# STM32WB55xx register map
File version: 1.0
Registers are 32-bit, read-write, reset 0x0 unless marked. A register's access mark holds for its fields unless they carry their own. Offsets are from the block's base; [hi:lo] are bit positions; {n}, {i} and the like mark numbered series.

## RTC — Real-Time Clock
Base 0x40002800
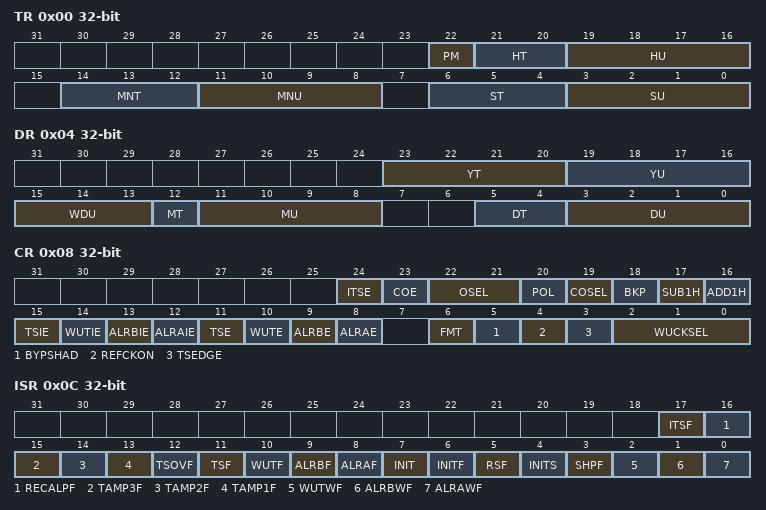
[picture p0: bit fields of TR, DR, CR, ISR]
0x00 TR — RTC time register
  [22] PM — AM/PM notation
    0=AM_OR_24 (AM or 24-hour format); 1=PM
  [21:20] HT — Hour tens in BCD format
  [19:16] HU — Hour units in BCD format
  [14:12] MNT — Minute tens in BCD format
  [11:8] MNU — Minute unit in BCD format
  [6:4] ST — Second tens in BCD format
  [3:0] SU — Second units in BCD format
0x04 DR — RTC date register
  [23:20] YT — Year tens in BCD format
  [19:16] YU — Years units in BCD format
  [15:13] WDU — Week day units
  [12] MT — Month tens in BCD format
  [11:8] MU — Month units in BCD format
  [5:4] DT — Date tens in BCD format
  [3:0] DU — Date units in BCD format
0x08 CR — RTC control register
  [24] ITSE — Timestamp on internal event enable
  [23] COE — Calibration output enable
  [22:21] OSEL — Output selection
    0=DISABLE (Output disabled); 1=ALMA (Alarm A output enabled); 2=ALMB (Alarm B output enabled); 3=WAKEUP (Wakeup output enabled)
  [20] POL — Output polarity
    0=HIGH (Pin is high when ALRAF/ALRBF/WUTF is asserted (depending on OSEL)); 1=LOW (Pin is low when ALRAF/ALRBF/WUTF is asserted (depending on OSEL))
  [19] COSEL — Calibration output selection
  [18] BKP — Backup
  [17] SUB1H — Subtract 1 hour (winter time change)
  [16] ADD1H — Add 1 hour (summer time change)
  [15] TSIE — Time-stamp interrupt enable
  [14] WUTIE — Wakeup timer interrupt enable
  [13] ALRBIE — Alarm B interrupt enable
  [12] ALRAIE — Alarm A interrupt enable
  [11] TSE — Timestamp on RTC TS input edge enable
  [10] WUTE — Wakeup timer enable
  [9] ALRBE — Alarm B enable
  [8] ALRAE — Alarm A enable
  [6] FMT — Hour AM/PM or 24H format
    0=HOURFORMAT_24HOUR (24 hour/day format); 1=AMPM (AM/PM hour format)
  [5] BYPSHAD — Bypass the shadow registers
  [4] REFCKON — RTC_REFIN reference clock detection enable (50 or 60 Hz)
  [3] TSEDGE — Timestamp event active edge
    0=RISING (RTC_TS input rising edge generates a time-stamp event); 1=FALLING (RTC_TS input falling edge generates a time-stamp event)
  [2:0] WUCKSEL — Wakekup clock selection
    0=DIV_16 (RTC/16 clock is selected); 1=DIV_8 (RTC/8 clock is selected); 2=DIV_4 (RTC/4 clock is selected); 3=DIV_2 (RTC/2 clock is selected); 4=CKSPRE (ck_spre (usually 1 Hz) clock is selected); 6=CKSPRE_WUT (ck_spre (usually 1 Hz) clock is selected and 2exp16 is added to the WUT counter value)
0x0C ISR — RTC initialization and status register
  [17] ITSF — Internal timestamp flag
  [16] RECALPF — Recalibration pending flag
  [15] TAMP3F — RTC_TAMP3 detection flag
  [14] TAMP2F — RTC_TAMP2 detection flag
  [13] TAMP1F — RTC_TAMP1 detection flag
  [12] TSOVF — Timestamp overflow flag
  [11] TSF — Timestamp flag
  [10] WUTF — Wakeup timer flag
  [9] ALRBF — Alarm B flag
  [8] ALRAF — Alarm A flag
  [7] INIT — Initialization mode
  [6] INITF — Initialization flag
  [5] RSF — Registers synchronization flag
  [4] INITS — Initialization status flag
  [3] SHPF — Shift operation pending
  [2] WUTWF — Wakeup timer write flag
  [1] ALRBWF — Alarm B write flag
  [0] ALRAWF — Alarm A write flag
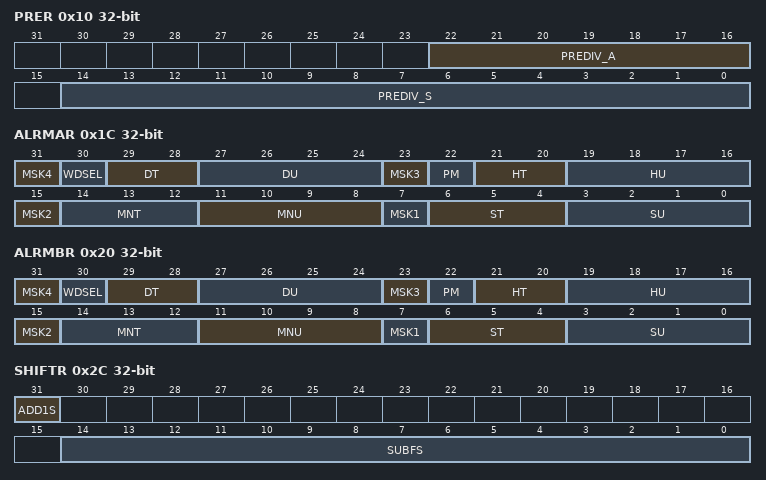
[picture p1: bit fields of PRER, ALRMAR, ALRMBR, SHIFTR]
0x10 PRER — RTC prescaler register
  [22:16] PREDIV_A — Asynchronous prescaler factor
  [14:0] PREDIV_S — Synchronous prescaler factor
0x14 WUTR — RTC wakeup timer register
  [15:0] WUT — Wakeup auto-reload value bits
0x1C ALRMAR — RTC alarm A register
  [31] MSK4 — Alarm A date mask
  [30] WDSEL — Alarm A week day selection
  [29:28] DT — Alarm A date tens in BCD format
  [27:24] DU — Alarm A date units in BCD format
  [23] MSK3 — Alarm A hours mask
  [22] PM — Alarm A AM/PM or 24H format
    0=AM (AM or 24-hour format); 1=PM
  [21:20] HT — Alarm A hour tens in BCD format
  [19:16] HU — Alarm A hour units in BCD format
  [15] MSK2 — Alarm A minutes mask
  [14:12] MNT — Alarm A minute tens in BCD format
  [11:8] MNU — Alarm A minute units in BCD format
  [7] MSK1 — Alarm A seconds mask
  [6:4] ST — Alarm A second tens in BCD format
  [3:0] SU — Alarm A second units in BCD format
0x20 ALRMBR — RTC alarm B register
  [31] MSK4 — Alarm B date mask
  [30] WDSEL — Alarm B week day selection
  [29:28] DT — Alarm B data tens in BCD format
  [27:24] DU — Alarm B data units or day in BCD format
  [23] MSK3 — Alarm B hour mask
  [22] PM — Alarm B AM/PM or 24H format
    0=AM (AM or 24-hour format); 1=PM
  [21:20] HT — Alarm B hour tens in BCD format
  [19:16] HU — Alarm B hour units in BCD format
  [15] MSK2 — Alarm B minutes mask
  [14:12] MNT — Alarm B minute tens in BCD format
  [11:8] MNU — Alarm B minute units in BCD format
  [7] MSK1 — Alarm B seconds mask
  [6:4] ST — Alarm B second tens in BCD format
  [3:0] SU — Alarm B second units in BCD format
0x24 WPR — RTC write protection register
  [7:0] KEY — Write protection key
0x28 SSR — RTC sub second register
  [15:0] SS — Sub second value
0x2C SHIFTR — RTC shift control register
  [31] ADD1S — Add on second
  [14:0] SUBFS — Subtract a fraction of a second
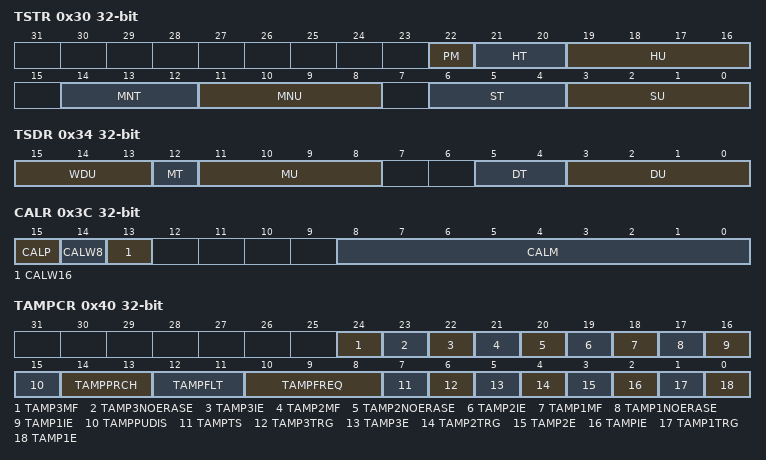
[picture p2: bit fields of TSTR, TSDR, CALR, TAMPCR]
0x30 TSTR — RTC time stamp time register
  [22] PM — Timestamp AM/PM or 24H format
    0=AM (AM or 24-hour format); 1=PM
  [21:20] HT — Timestamp hour tens in BCD format
  [19:16] HU — Timestamp hour units in BCD format
  [14:12] MNT — Timestamp minute tens in BCD format
  [11:8] MNU — Timestamp minute units in BCD format
  [6:4] ST — Timestamp second tens in BCD format
  [3:0] SU — Timestamp second units in BCD format
0x34 TSDR — RTC time stamp date register
  [15:13] WDU — Timestamp week day units
  [12] MT — Timestamp month tens in BCD format
  [11:8] MU — Timestamp month units in BCD format
  [5:4] DT — Timestamp date tens in BCD format
  [3:0] DU — Timestamp date units in BCD format
0x38 TSSSR — RTC time-stamp sub second register
  [15:0] SS — Timestamp sub second value
0x3C CALR — RTC calibration register
  [15] CALP — Increase frequency of RTC 488.5 ppm
    0=NONE (No RTCCLK pulses are added); 1=SET (One RTCCLK pulse is effectively inserted every 2exp11 pulses (frequency increased by 488.5 ppm))
  [14] CALW8 — Use a 8-second calibration cycle period
  [13] CALW16 — Use a 16-second calibration cycle period
  [8:0] CALM — Calibration minus
0x40 TAMPCR — RTC tamper configuration register
  [24] TAMP3MF — Tamper 3 generates a trigger event
  [23] TAMP3NOERASE — Tamper 3 no erase backup registers
  [22] TAMP3IE — Tamper 3 interrupt enable
  [21] TAMP2MF — Tamper 2 generates a trigger event
  [20] TAMP2NOERASE — Tamper 2 no erase backup registers
  [19] TAMP2IE — Tamper 2 interrupt enable
  [18] TAMP1MF — Tamper 1 generates a trigger event
  [17] TAMP1NOERASE — Tamper 1 no erase backup registers
  [16] TAMP1IE — Tamper 1 interrupt enable
  [15] TAMPPUDIS — RTC_TAMPx pull-up disable
  [14:13] TAMPPRCH — RTC_TAMPx precharge duration
    0=DURATION_1RTCCLK (Tamper pins are pre-charged before sampling during 1 RTCCLK cycle); 1=DURATION_2RTCCLK (Tamper pins are pre-charged before sampling during 2 RTCCLK cycles); 2=DURATION_4RTCCLK (Tamper pins are pre-charged before sampling during 4 RTCCLK cycles); 3=DURATION_8RTCCLK (Tamper pins are pre-charged before sampling during 8 RTCCLK cycles)
  [12:11] TAMPFLT — RTC_TAMPx filter count
    0=DISABLE (Tamper filter is disabled); 1=FILTER_2SAMPLE (Tamper is activated after 2 consecutive samples at the active level); 2=FILTER_4SAMPLE (Tamper is activated after 4 consecutive samples at the active level); 3=FILTER_8SAMPLE (Tamper is activated after 8 consecutive samples at the active level.)
  [10:8] TAMPFREQ — Tamper sampling frequency
    0=SAMPLFREQDIV_32768 (Each of the tamper inputs are sampled with a frequency = RTCCLK / 32768); 1=SAMPLFREQDIV_16384 (Each of the tamper inputs are sampled with a frequency = RTCCLK / 16384); 2=SAMPLFREQDIV_8192 (Each of the tamper inputs are sampled with a frequency = RTCCLK / 8192); 3=SAMPLFREQDIV_4096 (Each of the tamper inputs are sampled with a frequency = RTCCLK / 4096); 4=SAMPLFREQDIV_2048 (Each of the tamper inputs are sampled with a frequency = RTCCLK / 2048); 5=SAMPLFREQDIV_1024 (Each of the tamper inputs are sampled with a frequency = RTCCLK / 1024); 6=SAMPLFREQDIV_512 (Each of the tamper inputs are sampled with a frequency = RTCCLK / 512); 7=SAMPLFREQDIV_256 (Each of the tamper inputs are sampled with a frequency = RTCCLK / 256)
  [7] TAMPTS — Activate timestamp on tamper detection event
  [6] TAMP3TRG — Active level for RTC_TAMP3 input
  [5] TAMP3E — RTC_TAMP3 detection enable
  [4] TAMP2TRG — Active level for RTC_TAMP2 input
  [3] TAMP2E — RTC_TAMP2 detection enable
  [2] TAMPIE — Tampers interrupt enable
  [1] TAMP1TRG — Active level for RTC_TAMP1 input
  [0] TAMP1E — RTC_TAMP1 detection enable
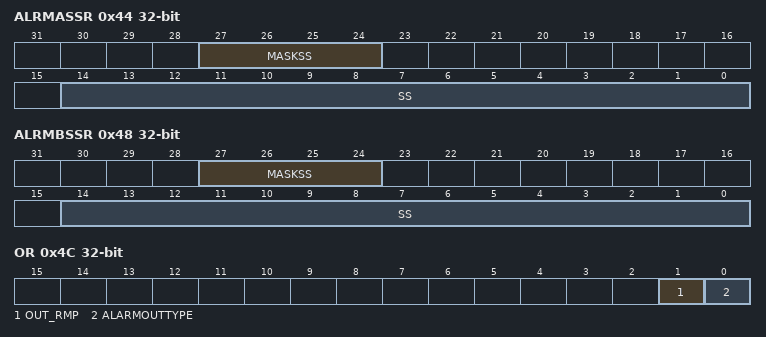
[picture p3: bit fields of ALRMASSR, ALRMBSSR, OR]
0x44 ALRMASSR — RTC alarm A sub second register
  [27:24] MASKSS — Alarm A mask the most-significant bits starting at this bit
  [14:0] SS
0x48 ALRMBSSR — RTC alarm B sub second register
  [27:24] MASKSS — Alarm B mask the most-significant bits starting at this bit
  [14:0] SS
0x4C OR — RTC option register
  [1] OUT_RMP — RTC_OUT remap
  [0] ALARMOUTTYPE — RTC_ALARM on PC13 output type
    0=OPENDRAIN (RTC_ALARM, when mapped on PC13, is open-drain output); 1=PUSHPULL (RTC_ALARM, when mapped on PC13, is push-pull output)
{0x50+4i} BKP{i}R (i=0..19) — RTC backup register {i}
